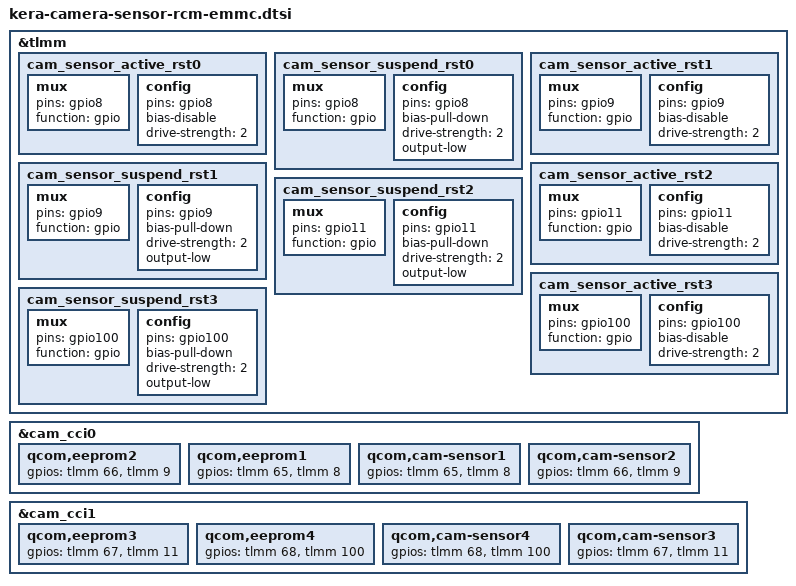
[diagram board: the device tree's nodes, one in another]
// SPDX-License-Identifier: BSD-3-Clause
/*
 * Copyright (c) Qualcomm Technologies, Inc. and/or its subsidiaries.
 */

&tlmm {
	cam_sensor_active_rst0: cam_sensor_active_rst0 {
		mux {
			pins = "gpio8";
			function = "gpio";
		};

		config {
			pins = "gpio8";
			bias-disable; /* No PULL */
			drive-strength = <2>; /* 2 MA */
		};
	};

	cam_sensor_suspend_rst0: cam_sensor_suspend_rst0 {
		mux {
			pins = "gpio8";
			function = "gpio";
		};

		config {
			pins = "gpio8";
			bias-pull-down; /* PULL DOWN */
			drive-strength = <2>; /* 2 MA */
			output-low;
		};
	};

	cam_sensor_active_rst1: cam_sensor_active_rst1 {
		mux {
			pins = "gpio9";
			function = "gpio";
		};

		config {
			pins = "gpio9";
			bias-disable; /* No PULL */
			drive-strength = <2>; /* 2 MA */
		};
	};

	cam_sensor_suspend_rst1: cam_sensor_suspend_rst1 {
		mux {
			pins = "gpio9";
			function = "gpio";
		};

		config {
			pins = "gpio9";
			bias-pull-down; /* PULL DOWN */
			drive-strength = <2>; /* 2 MA */
			output-low;
		};
	};

	cam_sensor_active_rst2: cam_sensor_active_rst2 {
		mux {
			pins = "gpio11";
			function = "gpio";
		};

		config {
			pins = "gpio11";
			bias-disable; /* No PULL */
			drive-strength = <2>; /* 2 MA */
		};
	};

	cam_sensor_suspend_rst2: cam_sensor_suspend_rst2 {
		mux {
			pins = "gpio11";
			function = "gpio";
		};

		config {
			pins = "gpio11";
			bias-pull-down; /* PULL DOWN */
			drive-strength = <2>; /* 2 MA */
			output-low;
		};
	};

	cam_sensor_active_rst3: cam_sensor_active_rst3 {
		mux {
			pins = "gpio100";
			function = "gpio";
		};

		config {
			pins = "gpio100";
			bias-disable; /* No PULL */
			drive-strength = <2>; /* 2 MA */
		};
	};

	cam_sensor_suspend_rst3: cam_sensor_suspend_rst3 {
		mux {
			pins = "gpio100";
			function = "gpio";
		};

		config {
			pins = "gpio100";
			bias-pull-down; /* PULL DOWN */
			drive-strength = <2>; /* 2 MA */
			output-low;
		};
	};
};

&cam_cci0 {
	qcom,eeprom2 {
		gpios = <&tlmm 66 0>,
			<&tlmm 9 0>;
	};

	qcom,eeprom1 {
		gpios = <&tlmm 65 0>,
			<&tlmm 8 0>;
	};

	qcom,cam-sensor1 {
		gpios = <&tlmm 65 0>,
			<&tlmm 8 0>;
	};

	qcom,cam-sensor2 {
		gpios = <&tlmm 66 0>,
			<&tlmm 9 0>;
	};
};

&cam_cci1 {
	qcom,eeprom3 {
		gpios = <&tlmm 67 0>,
			<&tlmm 11 0>;
	};

	qcom,eeprom4 {
		gpios = <&tlmm 68 0>,
			<&tlmm 100 0>;
	};

	qcom,cam-sensor4 {
		gpios = <&tlmm 68 0>,
			<&tlmm 100 0>;
	};

	qcom,cam-sensor3 {
		gpios = <&tlmm 67 0>,
			<&tlmm 11 0>;
	};
};
